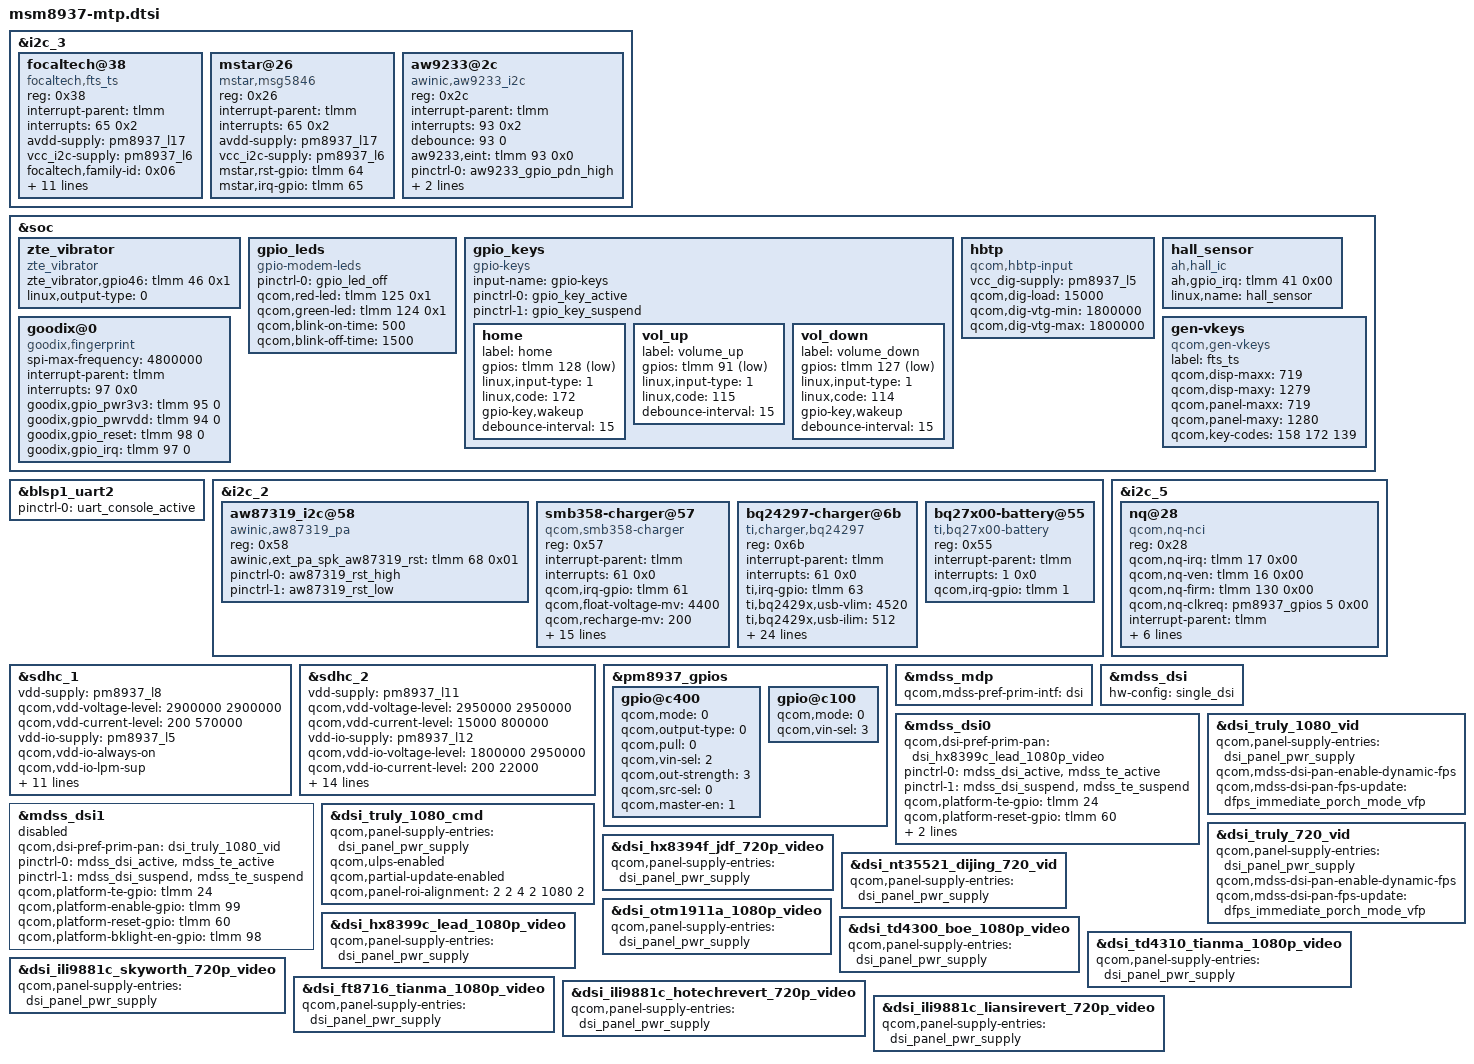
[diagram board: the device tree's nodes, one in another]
/*
 * Copyright (c) 2015-2016, The Linux Foundation. All rights reserved.
 *
 * This program is free software; you can redistribute it and/or modify
 * it under the terms of the GNU General Public License version 2 and
 * only version 2 as published by the Free Software Foundation.
 *
 * This program is distributed in the hope that it will be useful,
 * but WITHOUT ANY WARRANTY; without even the implied warranty of
 * MERCHANTABILITY or FITNESS FOR A PARTICULAR PURPOSE.  See the
 * GNU General Public License for more details.
 */

#include "msm8937-pinctrl.dtsi"
#include "msm8937-camera-sensor-mtp.dtsi"

/* add by wkh begin*/
&i2c_3 { /* BLSP1 QUP3 */
        focaltech@38{
			compatible = "focaltech,fts_ts";
			reg = <0x38>;
			interrupt-parent = <&tlmm>;
			interrupts = <65 0x2>;
			avdd-supply = <&pm8937_l17>;
			vcc_i2c-supply = <&pm8937_l6>;
			focaltech,family-id = <0x06>;
			focaltech,reset-gpio = <&tlmm 64 0x0>;
			focaltech,irq-gpio = <&tlmm 65 0x2008>;
			focaltech,display-coords = <0 0 720 1280>;
			focaltech,panel-coords = <0 0 720 1280>;
			focaltech,button-map= <158 172 139>;
			focaltech,hard-reset-delay-ms = <20>;
			focaltech,soft-reset-delay-ms = <150>;
			focaltech,num-max-touches = <5>;
			focaltech,no-force-update;
			focaltech,i2c-pull-up;
			focaltech,resume-in-workqueue;
		};
		mstar@26{
			compatible = "mstar,msg5846";
			reg = <0x26>;
			interrupt-parent = <&tlmm>;
			interrupts = <65 0x2>;
			avdd-supply = <&pm8937_l17>;
			vcc_i2c-supply = <&pm8937_l6>;
			mstar,rst-gpio = <&tlmm 64 0x0>;
			mstar,irq-gpio = <&tlmm 65 0x2008>;
			
			
		};
		aw9233@2c{
			compatible = "awinic,aw9233_i2c";
			reg = <0x2c>;
			interrupt-parent = <&tlmm>;
			interrupts = <93 0x2>;
			debounce = <93 0>;
			aw9233,eint = <&tlmm 93 0x0>;
			pinctrl-names = "aw9233_pdn_high","aw9233_pdn_low","aw9233_int_pin";
			pinctrl-0 = <&aw9233_gpio_pdn_high>;
			pinctrl-1 = <&aw9233_gpio_pdn_low>;
			pinctrl-2 = <&aw9233_gpio_int_pin>;
		};
};
/*  end by wkh */

/*&flash_led {
	compatible = "qcom,qpnp-flash-led";
	reg = <0xd300 0x100>;
//	pinctrl-names = "flash_led_enable","flash_led_disable";
//	pinctrl-0 = <&rear_flash_led_enable>;
//	pinctrl-1 = <&rear_flash_led_disable>;
	qcom,follow-otst2-rb-disabled;
};

&wled {
	qcom,cons-sync-write-delay-us = <1000>;
};*/

&soc {
/* added by zte_sw_heweiran 20160321 for vibrator */
	zte_vibrator {
		compatible = "zte_vibrator";
		zte_vibrator,gpio46 = <&tlmm 46 0x1>;
		linux,output-type = <0>;
	};  
/* added by zte_sw_heweiran 20160321 for vibrator */
/* added by zte_sw_chenyingfang for color_led,start */
	gpio_leds {
		compatible = "gpio-modem-leds";
		status = "okay";
		pinctrl-names = "default";
		pinctrl-0 = <&gpio_led_off>;
		qcom,red-led = <&tlmm 125 0x1>; 
		qcom,green-led = <&tlmm 124 0x1>; 
		/*qcom,trickle_red-led = <&tlmm 3 0x1>;*/
		qcom,blink-on-time = <500>;
		qcom,blink-off-time = <1500>;
	};  
	
/* added by zte_sw_chenyingfang for color_led,end */
	gpio_keys {
		compatible = "gpio-keys";
		input-name = "gpio-keys";
		pinctrl-names = "tlmm_gpio_key_active","tlmm_gpio_key_suspend";
		pinctrl-0 = <&gpio_key_active>;
		pinctrl-1 = <&gpio_key_suspend>;

		// ZTE_MODIFY start by dingli10091962
        home {
			label = "home";
			gpios = <&tlmm 128 0x1>;
			linux,input-type = <1>;
			linux,code = <172>;
			gpio-key,wakeup;    //add by xueqiang 1114
			debounce-interval = <15>;
		};

		//camera_snapshot {
		//	label = "camera_snapshot";
		//	gpios = <&tlmm 127 0x1>;
		//	linux,input-type = <1>;
		//	linux,code = <0x2fe>;
		//	debounce-interval = <15>;
		//};
        // ZTE_MODIFY end by dingli10091962

		vol_up {
			label = "volume_up";
			gpios = <&tlmm 91 0x1>;
			linux,input-type = <1>;
			linux,code = <115>;
			debounce-interval = <15>;
		};

		// ZTE_MODIFY start by dingli10091962
        vol_down {
			label = "volume_down";
			gpios = <&tlmm 127 0x1>;
			linux,input-type = <1>;
			linux,code = <114>;
			gpio-key,wakeup;
			debounce-interval = <15>;
		};
        // ZTE_MODIFY end by dingli10091962        
	};

	hbtp {
		compatible = "qcom,hbtp-input";
		vcc_dig-supply = <&pm8937_l5>;
		qcom,dig-load = <15000>;
		qcom,dig-vtg-min = <1800000>;
		qcom,dig-vtg-max = <1800000>;
	};

	hall_sensor {
		compatible = "ah,hall_ic";		
		ah,gpio_irq = <&tlmm 41 0x00>;
		linux,name = "hall_sensor";	
	};	
/*added by chenhui for goodix fingerprint*/
    goodix@0 {
        compatible = "goodix,fingerprint";
        spi-max-frequency = <4800000>;
        interrupt-parent = <&tlmm>;
        interrupts = <97 0x0>;
        goodix,gpio_pwr3v3 = <&tlmm 95 0>;
        goodix,gpio_pwrvdd = <&tlmm 94 0>;		
        goodix,gpio_reset = <&tlmm 98 0>;
        goodix,gpio_irq = <&tlmm 97 0>;
    }; 
/*added by chenhui for goodix fingerprint*/	

    gen-vkeys {
		compatible = "qcom,gen-vkeys";
		label = "fts_ts";
		qcom,disp-maxx = <719>;
		qcom,disp-maxy = <1279>;
		qcom,panel-maxx = <719>;
		qcom,panel-maxy = <1280>;
		qcom,key-codes = <158 172 139>;
	};
};

&blsp1_uart2 {
	status = "ok";
	pinctrl-names = "default";
	pinctrl-0 = <&uart_console_active>;
};

//&pmi_haptic{
//	qcom,actuator-type = "erm";
//};
//lll054850 add for aw87319 20161128
&i2c_2 {
		aw87319_i2c@58{
	        compatible = "awinic,aw87319_pa";
	        reg = <0x58>;
	        awinic,ext_pa_spk_aw87319_rst = <&tlmm 68 0x01>;
	        pinctrl-names = "aw87319_pa_active", "aw87319_pa_off";
	        pinctrl-0 = <&aw87319_rst_high>;
	        pinctrl-1 = <&aw87319_rst_low>;	
        };
	smb358-charger@57 {
		compatible = "qcom,smb358-charger";
		reg = <0x57>;
		interrupt-parent = <&tlmm>;
		interrupts = <61 0x0>;
		qcom,irq-gpio = <&tlmm 61 0x00>;
		//qcom,vcc-i2c-supply = <&pm8226_lvs1>;
		qcom,float-voltage-mv = <4400>;
		qcom,recharge-mv = <200>;
		
		//qcom,disable-apsd;
		qcom,chg-inhibit-disabled;
		qcom,bms-controlled-charging;
		qcom,fastchg-current-max-ma = <1800>;
		qcom,bms-psy-name = "bms";
		//qcom,chg-vadc = <&pm8226_vadc>;
		//qcom,chg-adc_tm = <&pm8226_adc_tm>;
		qcom,hot-bat-decidegc = <600>;
		qcom,cold-bat-decidegc = <0>;
		qcom,bat-present-decidegc = <200>;
		qcom,warm-bat-decidegc = <450>;
		qcom,cool-bat-decidegc = <100>;
		qcom,warm-bat-ma = <900>;
		qcom,cool-bat-ma = <900>;
		qcom,warm-bat-mv = <4100>;
		qcom,cool-bat-mv = <4400>;
		
		qcom,iterm-ma = <150>;
		//qcom,iterm-disabled;
		
		qcom,skip-usb-suspend-for-fake-battery;
		
		//smb358_charger_otg: qcom,smb358-boost-otg {
		//		regulator-name = "smb358_charger_otg";
		//};
	};
	bq24297-charger@6b {
		compatible = "ti,charger,bq24297";
		reg = <0x6b>;
		interrupt-parent = <&tlmm>;
		interrupts = <61 0x0>;
		
		ti,irq-gpio = <&tlmm 63 0x00>;
		//ti,otg-enable-gpio = <&tlmm 5 0x00>;
		
		//pinctrl-names = "pmx_otg_active";
		//pinctrl-0 = <&otg_int_active>;

		//regulator-name = "bq2419x_otg_vreg";
		
		ti,bq2429x,usb-vlim = <4520>;
		ti,bq2429x,usb-ilim = <512>;
		ti,bq2429x,usb-float-voltage-mv = <4400>;
		ti,bq2429x,usb-ichg = <512>;
		
		ti,bq2429x,ta-vlim = <4520>;
		ti,bq2429x,ta-ilim = <2000>;
		ti,bq2429x,ta-ichg = <1800>;
		ti,bq2429x,ta-float-voltage-mv = <4400>;
		ti,bq2429x,software-jeita-supported;
		ti,bq2429x,jeita-hot-degc = <600>;
		ti,bq2429x,jeita-warm-degc = <450>;
		ti,bq2429x,jeita-cool-degc = <100>;
		ti,bq2429x,jeita-cold-degc = <0>;
		ti,bq2429x,jeita-cool-ma = <1408>;
		ti,bq2429x,jeita-cool-mv = <4400>;
		ti,bq2429x,jeita-warm-ma = <1800>;
		ti,bq2429x,jeita-warm-mv = <4100>;
		ti,bq2429x,jeita-cold-hysteresis = <20>;
		ti,bq2429x,jeita-hot-hysteresis = <20>;
		ti,bq2429x,thermal-mitigation = <1800 1400 800 450>;
		
		ti,bq2429x,precharge-current = <384>;
		ti,bq2429x,termination-current = <256>;
		ti,bq2429x,boost-volt = <4998>;
		ti,bq2429x,boost-current = <1000>;
		ti,bq2429x,enable_term;
	};
	bq27x00-battery@55 {
		compatible = "ti,bq27x00-battery";
		reg = <0x55>;
		interrupt-parent = <&tlmm>;
		interrupts = <1 0x0>;
		qcom,irq-gpio = <&tlmm 1 0x00>;
	};
};
//lll054850 add for aw87319 20161128
&i2c_5 { /* BLSP2 QUP1 */
	nq@28 {
		compatible = "qcom,nq-nci";
		reg = <0x28>;
		qcom,nq-irq = <&tlmm 17 0x00>;
		qcom,nq-ven = <&tlmm 16 0x00>;
		qcom,nq-firm = <&tlmm 130 0x00>;
		qcom,nq-clkreq = <&pm8937_gpios 5 0x00>;
		interrupt-parent = <&tlmm>;
		qcom,clk-src = "BBCLK2";
		interrupts = <17 0>;
		interrupt-names = "nfc_irq";
		pinctrl-names = "nfc_active", "nfc_suspend";
		pinctrl-0 = <&nfc_int_active &nfc_disable_active>;
		pinctrl-1 = <&nfc_int_suspend &nfc_disable_suspend>;
		clocks = <&clock_gcc clk_bb_clk2_pin>;
		clock-names = "ref_clk";
	};
};

&sdhc_1 {
	/* device core power supply */
	vdd-supply = <&pm8937_l8>;
	qcom,vdd-voltage-level = <2900000 2900000>;
	qcom,vdd-current-level = <200 570000>;

	/* device communication power supply */
	vdd-io-supply = <&pm8937_l5>;
	qcom,vdd-io-always-on;
	qcom,vdd-io-lpm-sup;
	qcom,vdd-io-voltage-level = <1800000 1800000>;
	qcom,vdd-io-current-level = <200 325000>;

	pinctrl-names = "active", "sleep";
	pinctrl-0 = <&sdc1_clk_on &sdc1_cmd_on &sdc1_data_on &sdc1_rclk_on>;
	pinctrl-1 = <&sdc1_clk_off &sdc1_cmd_off &sdc1_data_off &sdc1_rclk_off>;

	qcom,clk-rates = <400000 20000000 25000000 50000000 100000000 192000000
								384000000>;
	qcom,nonremovable;
	qcom,bus-speed-mode = "HS400_1p8v", "HS200_1p8v", "DDR_1p8v";

	status = "ok";
};

&sdhc_2 {
	/* device core power supply */
	vdd-supply = <&pm8937_l11>;
	qcom,vdd-voltage-level = <2950000 2950000>;
	qcom,vdd-current-level = <15000 800000>;

	/* device communication power supply */
	vdd-io-supply = <&pm8937_l12>;
	qcom,vdd-io-voltage-level = <1800000 2950000>;
	qcom,vdd-io-current-level = <200 22000>;

	pinctrl-names = "active", "sleep";
	pinctrl-0 = <&sdc2_clk_on &sdc2_cmd_on &sdc2_data_on &sdc2_cd_on>;
	pinctrl-1 = <&sdc2_clk_off &sdc2_cmd_off &sdc2_data_off>;

	#address-cells = <0>;
	interrupt-parent = <&sdhc_2>;
	interrupts = <0 1 2>;
	#interrupt-cells = <1>;
	interrupt-map-mask = <0xffffffff>;
	interrupt-map = <0 &intc 0 125 0
		1 &intc 0 221 0
		2 &tlmm 67 0>;
	interrupt-names = "hc_irq", "pwr_irq", "status_irq";
	cd-gpios = <&tlmm 67 0x0>;

	qcom,clk-rates = <400000 20000000 25000000 50000000 100000000
								200000000>;
	qcom,bus-speed-mode = "SDR12", "SDR25", "SDR50", "DDR50", "SDR104";

	status = "ok";
};

&pm8937_gpios {
	gpio@c400 {
		qcom,mode = <0>;
		qcom,output-type = <0>;
		qcom,pull = <0>;
		qcom,vin-sel = <2>;
		qcom,out-strength = <3>;
		qcom,src-sel = <0>;
		qcom,master-en = <1>;
		status = "okay";
	};
};

#include "msm8937-mdss-panels.dtsi"

&mdss_mdp {
	qcom,mdss-pref-prim-intf = "dsi";
};

&mdss_dsi {
	hw-config = "single_dsi";
};
//modify by yujianhua start
&mdss_dsi0 {
	qcom,dsi-pref-prim-pan = <&dsi_hx8399c_lead_1080p_video>;
	pinctrl-names = "mdss_default", "mdss_sleep";
	pinctrl-0 = <&mdss_dsi_active &mdss_te_active>;
	pinctrl-1 = <&mdss_dsi_suspend &mdss_te_suspend>;

	qcom,platform-te-gpio = <&tlmm 24 0>;
	//qcom,platform-enable-gpio = <&tlmm 99 0>;
	qcom,platform-reset-gpio = <&tlmm 60 0>;
	qcom,disp_vddio_en_gpio = <&tlmm 0 0>;
	qcom,disp_vddio_n_en_gpio = <&tlmm 2 0>;
	//qcom,platform-bklight-en-gpio = <&tlmm 98 0>;
};
//modify by yujianhua end

&mdss_dsi1 {
	status = "disabled";
	qcom,dsi-pref-prim-pan = <&dsi_truly_1080_vid>;
	pinctrl-names = "mdss_default", "mdss_sleep";
	pinctrl-0 = <&mdss_dsi_active &mdss_te_active>;
	pinctrl-1 = <&mdss_dsi_suspend &mdss_te_suspend>;

	qcom,platform-te-gpio = <&tlmm 24 0>;
	qcom,platform-enable-gpio = <&tlmm 99 0>;
	qcom,platform-reset-gpio = <&tlmm 60 0>;
	qcom,platform-bklight-en-gpio = <&tlmm 98 0>;
};

&dsi_truly_1080_vid {
	qcom,panel-supply-entries = <&dsi_panel_pwr_supply>;
	qcom,mdss-dsi-pan-enable-dynamic-fps;
	qcom,mdss-dsi-pan-fps-update = "dfps_immediate_porch_mode_vfp";
};

&dsi_truly_1080_cmd {
	qcom,panel-supply-entries = <&dsi_panel_pwr_supply>;
	qcom,ulps-enabled;
	qcom,partial-update-enabled;
	qcom,panel-roi-alignment = <2 2 4 2 1080 2>;
};

&dsi_truly_720_vid {
	qcom,panel-supply-entries = <&dsi_panel_pwr_supply>;
	qcom,mdss-dsi-pan-enable-dynamic-fps;
	qcom,mdss-dsi-pan-fps-update = "dfps_immediate_porch_mode_vfp";
};

//add by yujianhua start
&dsi_hx8394f_jdf_720p_video {
	qcom,panel-supply-entries = <&dsi_panel_pwr_supply>;
};
&dsi_nt35521_dijing_720_vid {
	qcom,panel-supply-entries = <&dsi_panel_pwr_supply>;
};
//add by yujianhua end

//add by zhanglian start
&dsi_hx8399c_lead_1080p_video {
	qcom,panel-supply-entries = <&dsi_panel_pwr_supply>;
};
//add by zhanglian end

&dsi_otm1911a_1080p_video {
	qcom,panel-supply-entries = <&dsi_panel_pwr_supply>;
};

&dsi_td4300_boe_1080p_video {
	qcom,panel-supply-entries = <&dsi_panel_pwr_supply>;
};

&dsi_td4310_tianma_1080p_video {
	qcom,panel-supply-entries = <&dsi_panel_pwr_supply>;
};

&dsi_ili9881c_skyworth_720p_video {
	qcom,panel-supply-entries = <&dsi_panel_pwr_supply>;
};

&dsi_ft8716_tianma_1080p_video {
	qcom,panel-supply-entries = <&dsi_panel_pwr_supply>;
};

&dsi_ili9881c_hotechrevert_720p_video {
	qcom,panel-supply-entries = <&dsi_panel_pwr_supply>;
};

&dsi_ili9881c_liansirevert_720p_video {
	qcom,panel-supply-entries = <&dsi_panel_pwr_supply>;
};

/* PM8937 GPIO configuration */
&pm8937_gpios {
	gpio@c100 {
		qcom,mode = <0>;
		qcom,vin-sel = <3>;
		status = "okay";
	};
};
